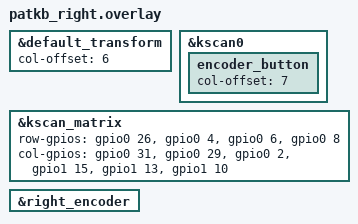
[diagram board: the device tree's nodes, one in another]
#include "patkb.dtsi"

&default_transform {
    col-offset = <6>;
};

&kscan0 {
    encoder_button {
        /* right encoder button is RC(0,13), the transform adds col-offset 6 */
        col-offset = <7>;
    };
};

/* The right pcb is the left one flipped: the columns run from right to left */
&kscan_matrix {
    row-gpios
        = <&gpio0 26 (GPIO_ACTIVE_HIGH | GPIO_PULL_DOWN)>
        , <&gpio0 4 (GPIO_ACTIVE_HIGH | GPIO_PULL_DOWN)>
        , <&gpio0 6 (GPIO_ACTIVE_HIGH | GPIO_PULL_DOWN)>
        , <&gpio0 8 (GPIO_ACTIVE_HIGH | GPIO_PULL_DOWN)>
        ;
    col-gpios
        = <&gpio0 31 GPIO_ACTIVE_HIGH>
        , <&gpio0 29 GPIO_ACTIVE_HIGH>
        , <&gpio0 2 GPIO_ACTIVE_HIGH>
        , <&gpio1 15 GPIO_ACTIVE_HIGH>
        , <&gpio1 13 GPIO_ACTIVE_HIGH>
        , <&gpio1 10 GPIO_ACTIVE_HIGH>
        ;
};

&right_encoder {
    status = "okay";
};
